# CC2340R5 register map
File version: 1.0
CPU: CM0P 1.0, other endian, MPU, FPU, 3 interrupt priority bits
Registers are 32-bit, read-write, reset 0x0 unless marked. A register's access mark holds for its fields unless they carry their own. Offsets are from the block's base; [hi:lo] are bit positions; lines under a group give offsets from that group; 'fields as' and 'values as' point back to an identical list.

## EVTULL — This is top module of ULL Event Fabric
Base 0x40005000
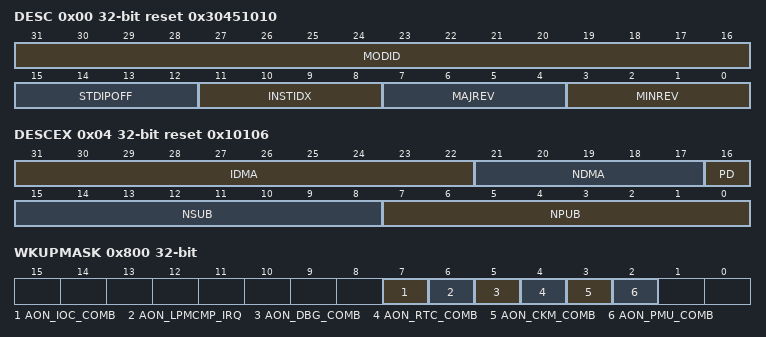
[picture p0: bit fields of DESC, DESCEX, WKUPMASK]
0x00 DESC reset 0x30451010 — Description Register. This register provides IP module ID, revision information, instance index and standard MMR registers offset.
  [31:16] MODID ro — [31:16] Module identifier used to uniquely identify this IP.
  [15:12] STDIPOFF ro — [15:12] Standard IP MMR block offset. Standard IP MMRs are the set of from aggregated IRQ registers till DTB. 0: Standard IP MMRs do not exist 0x1-0xF: Standard IP MMRs begin at offset of (64*STDIPOFF from the base IP address)
  [11:8] INSTIDX ro — [11:8] IP Instance ID number. If multiple instances of IP exist in the device, this field can identify the instance number (0-15).
  [7:4] MAJREV ro — [7:4] Major revision of IP (0-15).
  [3:0] MINREV ro — [3:0] Minor revision of IP (0-15).
0x04 DESCEX reset 0x10106 — Extended Description Register. This register provides configuration details of the IP to software drivers and end users.
  [31:22] IDMA ro — [31:22] Nember of DMA input channels
  [21:17] NDMA ro — [21:17] Number of DMA output channels
  [16] PD ro — [16:16] Power Domain. 0 : SVT 1 : ULL
  [15:8] NSUB ro — [15:8] Number of Subscribers
  [7:0] NPUB ro — [7:0] Number of Publishers
0x64 DTB — Digital test bus control register. This register can be used to bring out IP internal signals to the pads for observation. 16 signals can be observed per select value.
  [0] SEL — [0:0] Digital test bus selection mux control. Non-zero select values output a 16 bit selected group of signals per value.
    0=DIS (All 16 observation signals are set to zero.)
0x400 NMISEL — Output Selection for CPU NMI Interrupt
  [5:0] PUBID — [5:0] Read/write selection value. Writing any other value than values defined by a ENUM may result in undefined behavior.
    7=AON_IOC_COMB (IOC synchronous combined event, controlled by IOC:EVTCFG); 6=AON_LPMCMP_IRQ (AON LPCMP interrupt, controlled by SYS0:LPCMPCFG); 5=AON_DBG_COMB (DebugSS combined interrupt, interrupt flags can be found here DBGSS:MIS); 4=AON_RTC_COMB (AON_RTC event, controlled by the RTC:IMASK setting); 3=AON_CKM_COMB (CKMD combined interrupt request, interrupt flags can be found here CKMD:MIS); 2=AON_PMU_COMB (PMU combined interrupt request for BATMON, interrupt flags can be found here PMUD:EVENT); 0=NONE (Always inactive)
0x404 RTCCPTSEL — Output Selection for CPU Interrupt RTCCPT
  fields as NMISEL
0x800 WKUPMASK — WAKEUP Mask
  [7] AON_IOC_COMB — [7:7] Wake-up mask for AON_IOC_COMB. 0 - Wakeup Disabled 1 - Wakeup Enabled
  [6] AON_LPMCMP_IRQ — [6:6] Wake-up mask for AON_LPMCMP_IRQ. 0 - Wakeup Disabled 1 - Wakeup Enabled
  [5] AON_DBG_COMB — [5:5] Wake-up mask for AON_DBG_COMB. 0 - Wakeup Disabled 1 - Wakeup Enabled
  [4] AON_RTC_COMB — [4:4] Wake-up mask for AON_RTC_COMB. 0 - Wakeup Disabled 1 - Wakeup Enabled
  [3] AON_CKM_COMB — [3:3] Wake-up mask for AON_CKM_COMB. 0 - Wakeup Disabled 1 - Wakeup Enabled
  [2] AON_PMU_COMB — [2:2] Wake-up mask for AON_PMU_COMB. 0 - Wakeup Disabled 1 - Wakeup Enabled

## LRFDTXF
Base 0x40081800
0x00 TXD — TX FIFO data. When written the register data is pushed to the TX FIFO. When read, data is popped from the TX FIFO
  [31:0] DATA — [31:0] TX FIFO data. When written the register data is pushed to the TX FIFO. When read, data is popped from the TX FIFO. When writing or reading this register the access size will determine how many bytes are pushed to or popped from the FIFO. It is possible to push or pop 1,2 or 4 bytes depending on the access being done.

## LRFDRXF
Base 0x40081C00
0x00 RXD — RX FIFO data. When written the register data is pushed to the RX FIFO. When read, data is popped from the RX FIFO
  [31:0] DATA — [31:0] RX FIFO data. When written the register data is pushed to the RX FIFO. When read, data is popped from the RX FIFO. When writing or reading this register the access size will determine how many bytes are pushed to or popped from the FIFO. It is possible to push or pop 1,2 or 4 bytes depending on the access being done.
